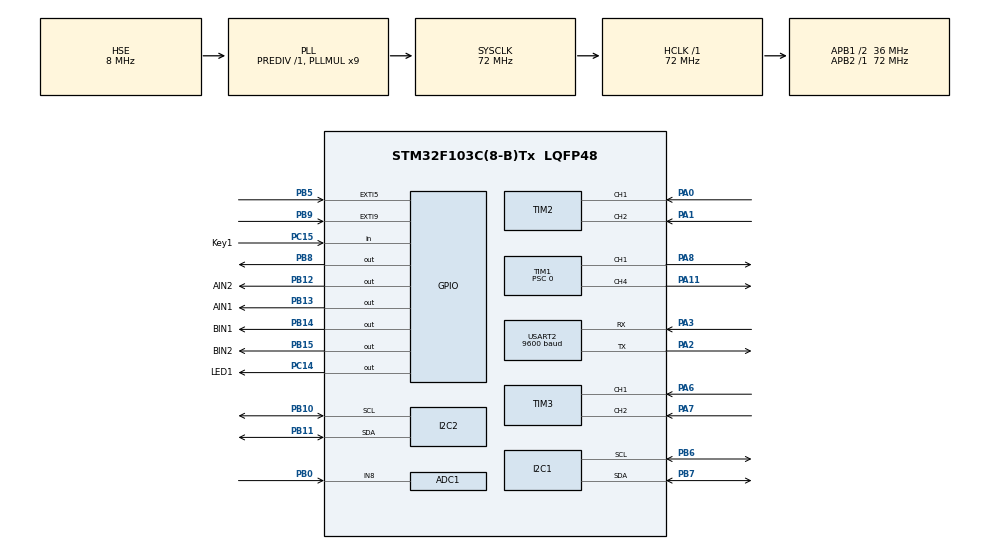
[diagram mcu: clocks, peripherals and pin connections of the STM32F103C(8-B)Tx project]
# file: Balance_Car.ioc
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ADC1.Channel-1\#ChannelRegularConversion=ADC_CHANNEL_8
ADC1.ContinuousConvMode=DISABLE
ADC1.EnableInjectedConversion=DISABLE
ADC1.NbrOfConversion=1
ADC1.NbrOfConversionFlag=1
ADC1.Rank-1\#ChannelRegularConversion=1
ADC1.SamplingTime-1\#ChannelRegularConversion=ADC_SAMPLETIME_1CYCLE_5
ADC1.master=1
I2C1.I2C_Mode=I2C_Fast
I2C2.I2C_Mode=I2C_Fast
Mcu.Family=STM32F1
Mcu.Name=STM32F103C(8-B)Tx
Mcu.Package=LQFP48
NVIC.EXTI9_5_IRQn=true\:0\:0\:false\:false\:true\:true\:true\:true
NVIC.I2C1_EV_IRQn=true\:0\:0\:false\:false\:true\:true\:true\:true
NVIC.PriorityGroup=NVIC_PRIORITYGROUP_4
NVIC.TIM1_BRK_IRQn=true\:0\:0\:false\:false\:true\:true\:true\:true
NVIC.TIM1_CC_IRQn=true\:0\:0\:false\:false\:true\:true\:true\:true
NVIC.TIM1_TRG_COM_IRQn=true\:0\:0\:false\:false\:true\:true\:true\:true
NVIC.TIM1_UP_IRQn=true\:0\:0\:false\:false\:true\:true\:true\:true
NVIC.TIM4_IRQn=true\:0\:0\:false\:false\:true\:true\:true\:true
NVIC.USART2_IRQn=true\:0\:0\:false\:false\:true\:true\:true\:true
PA0-WKUP.Signal=S_TIM2_CH1_ETR
PA1.Signal=S_TIM2_CH2
PA11.Signal=S_TIM1_CH4
PA13.Mode=Serial_Wire
PA13.Signal=SYS_JTMS-SWDIO
PA14.Mode=Serial_Wire
PA14.Signal=SYS_JTCK-SWCLK
PA2.Mode=Asynchronous
PA2.Signal=USART2_TX
PA3.Mode=Asynchronous
PA3.Signal=USART2_RX
PA6.Signal=S_TIM3_CH1
PA7.Signal=S_TIM3_CH2
PA8.Signal=S_TIM1_CH1
PB0.Signal=ADCx_IN8
PB10.Mode=I2C
PB10.Signal=I2C2_SCL
PB11.Mode=I2C
PB11.Signal=I2C2_SDA
PB12.GPIO_Label=AIN2
PB12.Signal=GPIO_Output
PB13.GPIO_Label=AIN1
PB13.Signal=GPIO_Output
PB14.GPIO_Label=BIN1
PB14.Signal=GPIO_Output
PB15.GPIO_Label=BIN2
PB15.Signal=GPIO_Output
PB5.Signal=GPXTI5
PB6.Mode=I2C
PB6.Signal=I2C1_SCL
PB7.Mode=I2C
PB7.Signal=I2C1_SDA
PB8.GPIO_Speed=GPIO_SPEED_FREQ_HIGH
PB8.PinState=GPIO_PIN_RESET
PB8.Signal=GPIO_Output
PB9.Signal=GPXTI9
PC14-OSC32_IN.GPIO_Label=LED1
PC14-OSC32_IN.GPIO_ModeDefaultOutputPP=GPIO_MODE_OUTPUT_PP
PC14-OSC32_IN.GPIO_PuPd=GPIO_NOPULL
PC14-OSC32_IN.GPIO_Speed=GPIO_SPEED_FREQ_LOW
PC14-OSC32_IN.PinState=GPIO_PIN_RESET
PC14-OSC32_IN.Signal=GPIO_Output
PC15-OSC32_OUT.GPIO_Label=Key1
PC15-OSC32_OUT.GPIO_PuPd=GPIO_PULLUP
PC15-OSC32_OUT.Signal=GPIO_Input
PD0-OSC_IN.Mode=HSE-External-Oscillator
PD0-OSC_IN.Signal=RCC_OSC_IN
PD1-OSC_OUT.Mode=HSE-External-Oscillator
PD1-OSC_OUT.Signal=RCC_OSC_OUT
ProjectManager.HeapSize=0x200
ProjectManager.StackSize=0x400
ProjectManager.TargetToolchain=STM32CubeIDE
RCC.ADCPresc=RCC_ADCPCLK2_DIV6
RCC.AHBFreq_Value=72000000
RCC.APB1CLKDivider=RCC_HCLK_DIV2
RCC.APB1Freq_Value=36000000
RCC.APB1TimFreq_Value=72000000
RCC.APB2Freq_Value=72000000
RCC.APB2TimFreq_Value=72000000
RCC.HCLKFreq_Value=72000000
RCC.PLLMUL=RCC_PLL_MUL9
RCC.PLLSourceVirtual=RCC_PLLSOURCE_HSE
RCC.SYSCLKFreq_VALUE=72000000
RCC.SYSCLKSource=RCC_SYSCLKSOURCE_PLLCLK
RCC.USBFreq_Value=72000000
SH.ADCx_IN8.0=ADC1_IN8,IN8
SH.S_TIM1_CH1.0=TIM1_CH1,PWM Generation1 CH1
SH.S_TIM1_CH4.0=TIM1_CH4,PWM Generation4 CH4
SH.S_TIM2_CH1_ETR.0=TIM2_CH1,Encoder_Interface
SH.S_TIM2_CH2.0=TIM2_CH2,Encoder_Interface
SH.S_TIM3_CH1.0=TIM3_CH1,Encoder_Interface
SH.S_TIM3_CH2.0=TIM3_CH2,Encoder_Interface
TIM1.Channel-PWM\ Generation1\ CH1=TIM_CHANNEL_1
TIM1.Channel-PWM\ Generation4\ CH4=TIM_CHANNEL_4
TIM1.Period=7200-1
TIM1.Prescaler=0
TIM2.IC1Filter=10
TIM2.IC2Filter=10
TIM3.IC1Filter=10
TIM3.IC1Prescaler=TIM_ICPSC_DIV1
TIM3.IC2Filter=10
TIM3.IC2Prescaler=TIM_ICPSC_DIV1
TIM4.Period=65535
TIM4.Prescaler=72-1
USART2.BaudRate=9600
USART2.VirtualMode=VM_ASYNC
VP_TIM1_VS_ClockSourceINT.Mode=Internal
VP_TIM4_VS_ClockSourceINT.Mode=Internal
board=custom

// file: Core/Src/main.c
/* USER CODE BEGIN Header */
/**
  ******************************************************************************
  * @file           : main.c
  * @brief          : Main program body
  ******************************************************************************
  * @attention
  *
  * Copyright (c) 2024 STMicroelectronics.
  * All rights reserved.
  *
  * This software is licensed under terms that can be found in the LICENSE file
  * in the root directory of this software component.
  * If no LICENSE file comes with this software, it is provided AS-IS.
  *
  ******************************************************************************
  */
/* USER CODE END Header */
#include "main.h"
#include "adc.h"
#include "i2c.h"
#include "tim.h"
#include "usart.h"
#include "gpio.h"

/* USER CODE BEGIN Includes */
#include "user_main.h"
/* USER CODE END Includes */

void SystemClock_Config(void);

/* USER CODE BEGIN 0 */
/**
  * 函数功能: 按键外部中断回调函数
  * 输入参数: GPIO_Pin：中断引脚
  * 返 回 值: 无
  * 说    明: 无
  */

/* USER CODE END 0 */

int main(void)
{

  /* MCU Configuration--------------------------------------------------------*/

  /* Reset of all peripherals, Initializes the Flash interface and the Systick. */
  HAL_Init();

  /* Configure the system clock */
  SystemClock_Config();

  /* Initialize all configured peripherals */
  MX_GPIO_Init();
  MX_I2C1_Init();
  MX_ADC1_Init();
  MX_TIM2_Init();
  MX_TIM1_Init();
  MX_TIM4_Init();
  MX_TIM3_Init();
  MX_I2C2_Init();
  MX_USART2_UART_Init();

  /* Infinite loop */
  /* USER CODE BEGIN WHILE */
  while (1)
  {
      user_main();
    /* USER CODE END WHILE */

  }
}

void SystemClock_Config(void)
{
  RCC_OscInitTypeDef RCC_OscInitStruct = {0};
  RCC_ClkInitTypeDef RCC_ClkInitStruct = {0};
  RCC_PeriphCLKInitTypeDef PeriphClkInit = {0};

  /** Initializes the RCC Oscillators according to the specified parameters
  * in the RCC_OscInitTypeDef structure.
  */
  RCC_OscInitStruct.OscillatorType = RCC_OSCILLATORTYPE_HSE;
  RCC_OscInitStruct.HSEState = RCC_HSE_ON;
  RCC_OscInitStruct.HSEPredivValue = RCC_HSE_PREDIV_DIV1;
  RCC_OscInitStruct.HSIState = RCC_HSI_ON;
  RCC_OscInitStruct.PLL.PLLState = RCC_PLL_ON;
  RCC_OscInitStruct.PLL.PLLSource = RCC_PLLSOURCE_HSE;
  RCC_OscInitStruct.PLL.PLLMUL = RCC_PLL_MUL9;
  if (HAL_RCC_OscConfig(&RCC_OscInitStruct) != HAL_OK)
  {
    Error_Handler();
  }

  /** Initializes the CPU, AHB and APB buses clocks
  */
  RCC_ClkInitStruct.ClockType = RCC_CLOCKTYPE_HCLK|RCC_CLOCKTYPE_SYSCLK
                              |RCC_CLOCKTYPE_PCLK1|RCC_CLOCKTYPE_PCLK2;
  RCC_ClkInitStruct.SYSCLKSource = RCC_SYSCLKSOURCE_PLLCLK;
  RCC_ClkInitStruct.AHBCLKDivider = RCC_SYSCLK_DIV1;
  RCC_ClkInitStruct.APB1CLKDivider = RCC_HCLK_DIV2;
  RCC_ClkInitStruct.APB2CLKDivider = RCC_HCLK_DIV1;

  if (HAL_RCC_ClockConfig(&RCC_ClkInitStruct, FLASH_LATENCY_2) != HAL_OK)
  {
    Error_Handler();
  }
  PeriphClkInit.PeriphClockSelection = RCC_PERIPHCLK_ADC;
  PeriphClkInit.AdcClockSelection = RCC_ADCPCLK2_DIV6;
  if (HAL_RCCEx_PeriphCLKConfig(&PeriphClkInit) != HAL_OK)
  {
    Error_Handler();
  }
}

void Error_Handler(void)
{
  __disable_irq();
  while (1)
  {
  }
}
